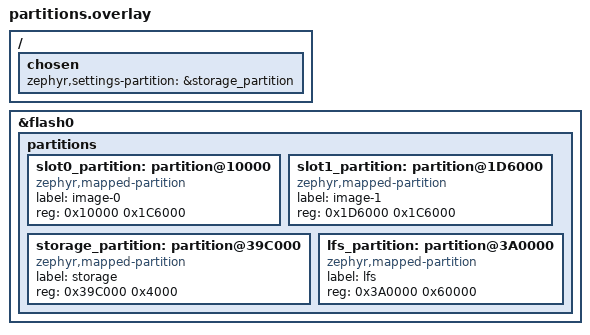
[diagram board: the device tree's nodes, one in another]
/*
 * Flash partition layout — SHARED by the app image and MCUboot.
 *
 * Fed to BOTH images (app via EXTRA_DTC_OVERLAY_FILE, MCUboot via
 * mcuboot_EXTRA_DTC_OVERLAY_FILE in sysbuild/CMakeLists.txt) so their flash maps
 * are identical — otherwise MCUboot stages/looks for the OTA image at a different
 * address than the app writes it to and OTA silently reverts on reboot.
 *
 * slot0 starts at 0x10000 (right after the 64KB MCUboot region), matching the
 * Arduino/ESP-IDF app offset (Mesh America "flash-update" compatible). The stock
 * sys / lpcore / scratch / coredump partitions are reclaimed. The two app slots
 * are equal size and end exactly where storage and lfs begin, so a -merged
 * reflash rewrites only MCUboot + slot0 and leaves identity, prefs, contacts and
 * BLE bonds intact.
 *
 * Nothing here is inherited: the base table is partitions_0x0_default_4M.dtsi
 * (see the DTS) and every label below is deleted and redefined.
 *
 * 4MB layout.
 */
/delete-node/ &sys_partition;
/delete-node/ &slot0_lpcore_partition;
/delete-node/ &slot1_lpcore_partition;
/delete-node/ &storage_partition;
/delete-node/ &coredump_partition;
/delete-node/ &slot0_partition;
/delete-node/ &slot1_partition;

/ {
	chosen {
		zephyr,settings-partition = &storage_partition;
	};
};

&flash0 {
	partitions {
		/* App slots — slot0 at 0x10000. sysbuild.conf selects MCUboot
		 * OVERWRITE_ONLY, but keeping them equal size leaves swap available. */
		slot0_partition: partition@10000 {
			compatible = "zephyr,mapped-partition";
			label = "image-0";
			reg = <0x10000 0x1C6000>;
		};
		slot1_partition: partition@1D6000 {
			compatible = "zephyr,mapped-partition";
			label = "image-1";
			reg = <0x1D6000 0x1C6000>;
		};
		/* BLE bond NVS — above slot1, so bonds survive a -merged reflash. */
		storage_partition: partition@39C000 {
			compatible = "zephyr,mapped-partition";
			label = "storage";
			reg = <0x39C000 0x4000>;
		};
		/* LittleFS (identity/prefs/contacts) — above slot1, same reason. */
		lfs_partition: partition@3A0000 {
			compatible = "zephyr,mapped-partition";
			label = "lfs";
			reg = <0x3A0000 0x60000>;
		};
	};
};
